# CC2538NF53 register map
File version: 1.0
CPU: CM3 1.0, other endian, MPU, FPU, 3 interrupt priority bits
Registers are 32-bit, read-write, reset 0x0 unless marked. A register's access mark holds for its fields unless they carry their own. Offsets are from the block's base; [hi:lo] are bit positions; {n}, {i} and the like mark numbered series.

## AES (part 2 of 2) — Register fields should be considered static unless otherwise noted as dynamic.
Base 0x4008B000
0x570 AES_TAG_OUT_0 — TAG registers The tag registers can be accessed via DMA or directly with host reads. These registers buffer the TAG from the EIP-120t. The registers are shared with the intermediate authentication result registers, but cannot be read until the processing is finished. While processing, a read from these registers returns 0s. If an operation does not return a TAG, reading from these registers returns an IV. If an operation returns a TAG plus an IV and both need to be read by the host, the host must first read the TAG followed by the IV. Reading these in reverse order will return the IV twice.
  [31:0] AES_TAG — [31:0] AES_TAG[31:0] Bits [31:0] of the AES_TAG registers store the authentication value for the combined and authentication only modes. For a host read operation, these registers contain the last 128-bit TAG output of the EIP-120t; the TAG is available until the next context is written. This register will only contain valid data if the TAG is available and when the store_ready bit from AES_CTRL register is set. During processing or for operations/modes that do not return a TAG, reads from this register return data from the IV register.
{0x570+4i} AES_TAG_OUT_{i} (i=1..3) — TAG registers The tag registers can be accessed via DMA or directly with host reads. These registers buffer the TAG from the EIP-120t. The registers are shared with the intermediate authentication result registers, but cannot be read until the processing is finished. While processing, a read from these registers returns 0s. If an operation does not return a TAG, reading from these registers returns an IV. If an operation returns a TAG plus an IV and both need to be read by the host, the host must first read the TAG followed by the IV. Reading these in reverse order returns the IV twice.
  [31:0] AES_TAG — [31:0] AES_TAG[{32i+31}:{32i}] For a host read operation, these registers contain the last 128-bit TAG output of the EIP-120t; the TAG is available until the next context is written. This register contains valid data only if the TAG is available and when the store_ready bit from AES_CTRL register is set. During processing or for operations/modes that do not return a TAG, reads from this register return data from the IV register.
{0x600+4i} HASH_DATA_IN_{i} (i=0..15) — HASH data input registers The data input registers should be used to provide input data to the hash module through the slave interface.
  [31:0] HASH_DATA_IN — [31:0] HASH_DATA_IN[{32i+31}:{32i}] These registers must be written with the 512-bit input data. The data lines are connected directly to the data input of the hash module and hence into the engine's internal data buffer. Writing to each of the registers triggers a corresponding 32-bit write enable to the internal buffer. Note: The host may only write the input data buffer when the rfd_in bit of the HASH_IO_BUF_CTRL register is high. If the rfd_in bit is 0, the engine is busy with processing. During processing, it is not allowed to write new input data. For message lengths larger than 64 bytes, multiple blocks of data are written to this input buffer using a handshake through flags of the HASH_IO_BUF_CTRL register. All blocks except the last are required to be 512 bits in size. If the last block is not 512 bits long, only the least significant bits of data must be written, but they must be padded with 0s to the next 32-bit boundary. Host read operations from these register addresses return 0s.
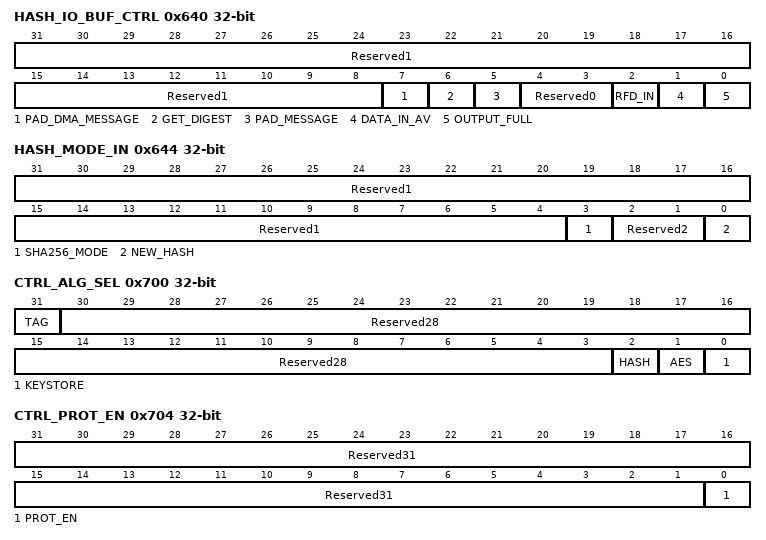
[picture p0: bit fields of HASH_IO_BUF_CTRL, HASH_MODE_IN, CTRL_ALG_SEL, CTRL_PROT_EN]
0x640 HASH_IO_BUF_CTRL — Input/output buffer control and status register This register pair shares a single address location and contains bits that control and monitor the data flow between the host and the hash engine.
  [31:8] Reserved1 — [31:8] Write 0s and ignore on reading
  [7] PAD_DMA_MESSAGE — [7:7] Note: This bit must only be used when data is supplied through the DMA. It should not be used when data is supplied through the slave interface. This bit indicates whether the hash engine has to pad the message, received through the DMA and finalize the hash. When set to 1, the hash engine pads the last block using the programmed length. After padding, the final hash result is calculated. When set to 0, the hash engine treats the last written block as block-size aligned and calculates the intermediate digest. This bit is automatically cleared when the last DMA data block is arrived in the hash engine.
  [6] GET_DIGEST — [6:6] Note: The bit description below is only applicable when data is sent through the slave interface. This bit must be set to 0 when data is received through the DMA. This bit indicates whether the hash engine should provide the hash digest. When provided simultaneously with data_in_av, the hash digest is provided after processing the data that is currently in the HASH_DATA_IN register. When provided without data_in_av, the current internal digest buffer value is copied to the HASH_DIGEST_n registers. The host must write a 1 to this bit to make the intermediate hash digest available. Writing 0 to this bit has no effect. This bit is automatically cleared (that is, reads 0) when the hash engine has processed the contents of the HASH_DATA_IN register. In the period between this bit is set by the host and the actual HASH_DATA_IN processing, this bit reads 1.
  [5] PAD_MESSAGE — [5:5] Note: The bit description below is only applicable when data is sent through the slave interface. This bit must be set to 0 when data is received through the DMA. This bit indicates that the HASH_DATA_IN registers hold the last data of the message and hash padding must be applied. The host must write this bit to 1 in order to indicate to the hash engine that the HASH_DATA_IN register currently holds the last data of the message. When pad_message is set to 1, the hash engine will add padding bits to the data currently in the HASH_DATA_IN register. When the last message block is smaller than 512 bits, the pad_message bit must be set to 1 together with the data_in_av bit. When the last message block is equal to 512 bits, pad_message may be set together with data_in_av. In this case the pad_message bit may also be set after the last data block has been written to the hash engine (so when the rfd_in bit has become 1 again after writing the last data block). Writing 0 to this bit has no effect. This bit is automatically cleared (i.e. reads 0) by the hash engine. This bit reads 1 between the time it was set by the host and the hash engine interpreted its value.
  [4:3] Reserved0 — [4:3] Write 0s and ignore on reading
  [2] RFD_IN — [2:2] Note: The bit description below is only applicable when data is sent through the slave interface. This bit can be ignored when data is received through the DMA. Read-only status of the input buffer of the hash engine. When 1, the input buffer of the hash engine can accept new data; the HASH_DATA_IN registers can safely be populated with new data. When 0, the input buffer of the hash engine is processing the data that is currently in HASH_DATA_IN; writing new data to these registers is not allowed.
  [1] DATA_IN_AV — [1:1] Note: The bit description below is only applicable when data is sent through the slave interface. This bit must be set to 0 when data is received through the DMA. This bit indicates that the HASH_DATA_IN registers contain new input data for processing. The host must write a 1 to this bit to start processing the data in HASH_DATA_IN; the hash engine will process the new data as soon as it is ready for it (rfd_in bit is 1). Writing 0 to this bit has no effect. This bit is automatically cleared (i.e. reads as 0) when the hash engine starts processing the HASH_DATA_IN contents. This bit reads 1 between the time it was set by the host and the hash engine actually starts processing the input data block.
  [0] OUTPUT_FULL — [0:0] Indicates that the output buffer registers (HASH_DIGEST_n) are available for reading by the host. When this bit reads 0, the output buffer registers are released; the hash engine is allowed to write new data to it. In this case, the registers should not be read by the host. When this bit reads 1, the hash engine has stored the result of the latest hash operation in the output buffer registers. As long as this bit reads 1, the host may read output buffer registers and the hash engine is prevented from writing new data to the output buffer. After retrieving the hash result data from the output buffer, the host must write a 1 to this bit to clear it. This makes the digest output buffer available for the hash engine to store new hash results. Writing 0 to this bit has no effect. Note: If this bit is asserted (1) no new operation should be started before the digest is retrieved from the hash engine and this bit is cleared (0).
0x644 HASH_MODE_IN — Hash mode register
  [31:4] Reserved1 — [31:4] Write 0s and ignore on reading
  [3] SHA256_MODE — [3:3] The host must write this bit with 1 before processing a hash session.
  [2:1] Reserved2 — [2:1] Write 0s and ignore on reading
  [0] NEW_HASH — [0:0] When set to 1, it indicates that the hash engine must start processing a new hash session. The HASH_DIGEST_n registers will automatically be loaded with the initial hash algorithm constants of the selected hash algorithm. When this bit is 0 while the hash processing is started, the initial hash algorithm constants are not loaded in the HASH_DIGEST_n registers. The hash engine will start processing with the digest that is currently in its internal HASH_DIGEST_n registers. This bit is automatically cleared when hash processing is started.
0x648 HASH_LENGTH_IN_L — Hash length register
  [31:0] LENGTH_IN — [31:0] LENGTH_IN[31:0] Message length registers. The content of these registers is used by the hash engine during the message padding phase of the hash session. The data lines of this registers are directly connected to the interface of the hash engine. For a write operation by the host, these registers should be written with the message length in bits. Final hash operations: The total input data length must be programmed for new hash operations that require finalization (padding). The input data must be provided through the slave or DMA interface. Continued hash operations (finalized): For continued hash operations that require finalization, the total message length must be programmed, including the length of previously hashed data that corresponds to the written input digest. Non-final hash operations: For hash operations that do not require finalization (input data length is multiple of 512-bits which is SHA-256 data block size), the length field does not need to be programmed since not used by the operation. If the message length in bits is below (2^32-1), then only HASH_LENGTH_IN_L needs to be written. The hardware automatically sets HASH_LENGTH_IN_H to 0s in this case. The host may write the length register at any time during the hash session when the rfd_in bit of the HASH_IO_BUF_CTRL is high. The length register must be written before the last data of the active hash session is written into the hash engine. host read operations from these register locations will return 0s. Note: When getting data from DMA, this register must be programmed before DMA is programmed to start.
0x64C HASH_LENGTH_IN_H — Hash length register
  [31:0] LENGTH_IN — [31:0] LENGTH_IN[63:32] Message length registers. The content of these registers is used by the hash engine during the message padding phase of the hash session. The data lines of this registers are directly connected to the interface of the hash engine. For a write operation by the host, these registers should be written with the message length in bits. Final hash operations: The total input data length must be programmed for new hash operations that require finalization (padding). The input data must be provided through the slave or DMA interface. Continued hash operations (finalized): For continued hash operations that require finalization, the total message length must be programmed, including the length of previously hashed data that corresponds to the written input digest. Non-final hash operations: For hash operations that do not require finalization (input data length is multiple of 512-bits which is SHA-256 data block size), the length field does not need to be programmed since not used by the operation. If the message length in bits is below (2^32-1), then only HASH_LENGTH_IN_L needs to be written. The hardware automatically sets HASH_LENGTH_IN_H to 0s in this case. The host may write the length register at any time during the hash session when the rfd_in bit of the HASH_IO_BUF_CTRL is high. The length register must be written before the last data of the active hash session is written into the hash engine. host read operations from these register locations will return 0s. Note: When getting data from DMA, this register must be programmed before DMA is programmed to start.
0x650 HASH_DIGEST_A — Hash digest registers The hash digest registers consist of eight 32-bit registers, named HASH_DIGEST_A to HASH_DIGEST_H. After processing a message, the output digest can be read from these registers. These registers can be written with an intermediate hash result for continued hash operations.
  [31:0] HASH_DIGEST — [31:0] HASH_DIGEST[31:0] Hash digest registers Write operation: Continued hash: These registers should be written with the context data, before the start of a resumed hash session (the new_hash bit in the HASH_MODE register is 0 when starting a hash session). New hash: When initiating a new hash session (the new_hash bit in the HASH_MODE register is high), the internal digest registers are automatically set to the SHA-256 algorithm constant and these register should not be written. Reading from these registers provides the intermediate hash result (non-final hash operation) or the final hash result (final hash operation) after data processing.
0x654 HASH_DIGEST_B — Hash digest registers The hash digest registers consist of eight 32-bit registers, named HASH_DIGEST_A to HASH_DIGEST_H. After processing a message, the output digest can be read from these registers. These registers can be written with an intermediate hash result for continued hash operations.
  [31:0] HASH_DIGEST — [31:0] HASH_DIGEST[63:32] Hash digest registers Write operation: Continued hash: These registers should be written with the context data, before the start of a resumed hash session (the new_hash bit in the HASH_MODE register is 0 when starting a hash session). New hash: When initiating a new hash session (the new_hash bit in the HASH_MODE register is high), the internal digest registers are automatically set to the SHA-256 algorithm constant and these register should not be written. Reading from these registers provides the intermediate hash result (non-final hash operation) or the final hash result (final hash operation) after data processing.
0x658 HASH_DIGEST_C — Hash digest registers The hash digest registers consist of eight 32-bit registers, named HASH_DIGEST_A to HASH_DIGEST_H. After processing a message, the output digest can be read from these registers. These registers can be written with an intermediate hash result for continued hash operations.
  [31:0] HASH_DIGEST — [31:0] HASH_DIGEST[95:64] Hash digest registers Write operation: Continued hash: These registers should be written with the context data, before the start of a resumed hash session (the new_hash bit in the HASH_MODE register is 0 when starting a hash session). New hash: When initiating a new hash session (the new_hash bit in the HASH_MODE register is high), the internal digest registers are automatically set to the SHA-256 algorithm constant and these register should not be written. Reading from these registers provides the intermediate hash result (non-final hash operation) or the final hash result (final hash operation) after data processing.
0x65C HASH_DIGEST_D — Hash digest registers The hash digest registers consist of eight 32-bit registers, named HASH_DIGEST_A to HASH_DIGEST_H. After processing a message, the output digest can be read from these registers. These registers can be written with an intermediate hash result for continued hash operations.
  [31:0] HASH_DIGEST — [31:0] HASH_DIGEST[127:96] Hash digest registers Write operation: Continued hash: These registers should be written with the context data, before the start of a resumed hash session (the new_hash bit in the HASH_MODE register is 0 when starting a hash session). New hash: When initiating a new hash session (the new_hash bit in the HASH_MODE register is high), the internal digest registers are automatically set to the SHA-256 algorithm constant and these register should not be written. Reading from these registers provides the intermediate hash result (non-final hash operation) or the final hash result (final hash operation) after data processing.
0x660 HASH_DIGEST_E — Hash digest registers The hash digest registers consist of eight 32-bit registers, named HASH_DIGEST_A to HASH_DIGEST_H. After processing a message, the output digest can be read from these registers. These registers can be written with an intermediate hash result for continued hash operations.
  [31:0] HASH_DIGEST — [31:0] HASH_DIGEST[159:128] Hash digest registers Write operation: Continued hash: These registers should be written with the context data, before the start of a resumed hash session (the new_hash bit in the HASH_MODE register is 0 when starting a hash session). New hash: When initiating a new hash session (the new_hash bit in the HASH_MODE register is high), the internal digest registers are automatically set to the SHA-256 algorithm constant and these register should not be written. Reading from these registers provides the intermediate hash result (non-final hash operation) or the final hash result (final hash operation) after data processing.
0x664 HASH_DIGEST_F — Hash digest registers The hash digest registers consist of eight 32-bit registers, named HASH_DIGEST_A to HASH_DIGEST_H. After processing a message, the output digest can be read from these registers. These registers can be written with an intermediate hash result for continued hash operations.
  [31:0] HASH_DIGEST — [31:0] HASH_DIGEST[191:160] Hash digest registers Write operation: Continued hash: These registers should be written with the context data, before the start of a resumed hash session (the new_hash bit in the HASH_MODE register is 0 when starting a hash session). New hash: When initiating a new hash session (the new_hash bit in the HASH_MODE register is high), the internal digest registers are automatically set to the SHA-256 algorithm constant and these register should not be written. Reading from these registers provides the intermediate hash result (non-final hash operation) or the final hash result (final hash operation) after data processing.
0x668 HASH_DIGEST_G — Hash digest registers The hash digest registers consist of eight 32-bit registers, named HASH_DIGEST_A to HASH_DIGEST_H. After processing a message, the output digest can be read from these registers. These registers can be written with an intermediate hash result for continued hash operations.
  [31:0] HASH_DIGEST — [31:0] HASH_DIGEST[223:192] Hash digest registers Write operation: Continued hash: These registers should be written with the context data, before the start of a resumed hash session (the new_hash bit in the HASH_MODE register is 0 when starting a hash session). New hash: When initiating a new hash session (the new_hash bit in the HASH_MODE register is high), the internal digest registers are automatically set to the SHA-256 algorithm constant and these register should not be written. Reading from these registers provides the intermediate hash result (non-final hash operation) or the final hash result (final hash operation) after data processing.
0x66C HASH_DIGEST_H — Hash digest registers The hash digest registers consist of eight 32-bit registers, named HASH_DIGEST_A to HASH_DIGEST_H. After processing a message, the output digest can be read from these registers. These registers can be written with an intermediate hash result for continued hash operations.
  [31:0] HASH_DIGEST — [31:0] HASH_DIGEST[255:224] Hash digest registers Write operation: Continued hash: These registers should be written with the context data, before the start of a resumed hash session (the new_hash bit in the HASH_MODE register is 0 when starting a hash session). New hash: When initiating a new hash session (the new_hash bit in the HASH_MODE register is high), the internal digest registers are automatically set to the SHA-256 algorithm constant and these register should not be written. Reading from these registers provides the intermediate hash result (non-final hash operation) or the final hash result (final hash operation) after data processing.
0x700 CTRL_ALG_SEL — Algorithm select This algorithm selection register configures the internal destination of the DMA controller.
  [31] TAG — [31:31] If this bit is cleared to 0, the DMA operation involves only data. If this bit is set, the DMA operation includes a TAG (Authentication Result / Digest). For SHA-256 operation, a DMA must be set up for both input data and TAG. For any other selected module, setting this bit only allows a DMA that reads the TAG. No data allowed to be transferred to or from the selected module via the DMA.
  [30:3] Reserved28 — [30:3] Bits should be written with 0s and ignored on read.
  [2] HASH — [2:2] If set to one, selects the hash engine as destination for the DMA The maximum transfer size to DMA engine is set to 64 bytes for reading and 32 bytes for writing (the latter is only applicable if the hash result is written out through the DMA).
  [1] AES — [1:1] If set to one, selects the AES engine as source/destination for the DMA The read and write maximum transfer size to the DMA engine is set to 16 bytes.
  [0] KEYSTORE — [0:0] If set to one, selects the Key Store as destination for the DMA The maximum transfer size to DMA engine is set to 32 bytes (however transfers of 16, 24 and 32 bytes are allowed)
0x704 CTRL_PROT_EN — Master PROT privileged access enable This register enables the second bit (bit [1]) of the AHB HPROT bus of the AHB master interface when a read action of key(s) is performed on the AHB master interface for writing keys into the store module.
  [31:1] Reserved31 — [31:1] Bits should be written with 0s and ignored on read.
  [0] PROT_EN — [0:0] If this bit is cleared to 0, m_h_prot[1] on the AHB mater interface always remains 0. If this bit is set to one, the m_h_prot[1] signal on the master AHB bus is asserted to 1 if an AHB read operation is performed, using DMA, with the key store module as destination.
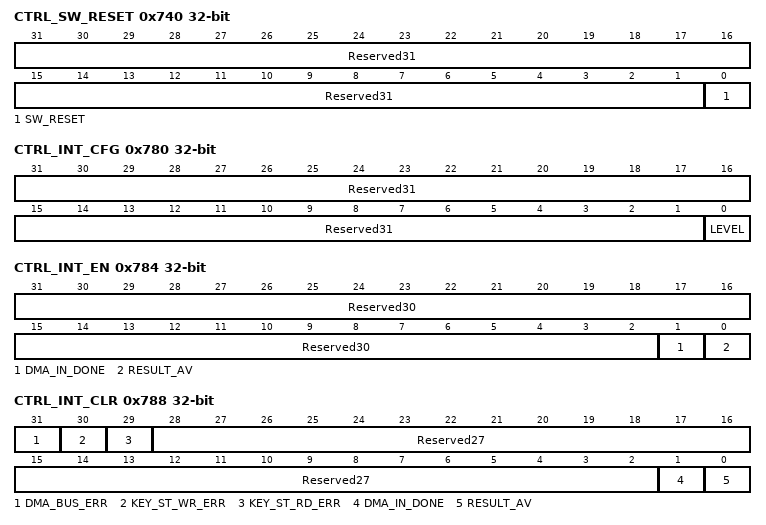
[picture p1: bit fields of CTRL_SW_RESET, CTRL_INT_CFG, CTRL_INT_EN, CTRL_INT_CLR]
0x740 CTRL_SW_RESET — Software reset
  [31:1] Reserved31 — [31:1] Bits should be written with 0s and ignored on read.
  [0] SW_RESET — [0:0] If this bit is set to 1, the following modules are reset: - Master control internal state is reset. That includes interrupt, error status register, and result available interrupt generation FSM. - Key store module state is reset. That includes clearing the written area flags; therefore, the keys must be reloaded to the key store module. Writing 0 has no effect. The bit is self cleared after executing the reset.
0x780 CTRL_INT_CFG — Interrupt configuration
  [31:1] Reserved31 — [31:1] Bits should be written with 0s and ignored on read.
  [0] LEVEL — [0:0] If this bit is 0, the interrupt output is a pulse. If this bit is set to 1, the interrupt is a level interrupt that must be cleared by writing the interrupt clear register. This bit is applicable for both interrupt output signals.
0x784 CTRL_INT_EN — Interrupt enable
  [31:2] Reserved30 — [31:2] Bits should be written with 0s and ignored on read.
  [1] DMA_IN_DONE — [1:1] If this bit is set to 0, the DMA input done (irq_dma_in_done) interrupt output is disabled and remains 0. If this bit is set to 1, the DMA input done interrupt output is enabled.
  [0] RESULT_AV — [0:0] If this bit is set to 0, the result available (irq_result_av) interrupt output is disabled and remains 0. If this bit is set to 1, the result available interrupt output is enabled.
0x788 CTRL_INT_CLR — Interrupt clear
  [31] DMA_BUS_ERR — [31:31] If 1 is written to this bit, the DMA bus error status is cleared. Writing 0 has no effect.
  [30] KEY_ST_WR_ERR — [30:30] If 1 is written to this bit, the key store write error status is cleared. Writing 0 has no effect.
  [29] KEY_ST_RD_ERR — [29:29] If 1 is written to this bit, the key store read error status is cleared. Writing 0 has no effect.
  [28:2] Reserved27 — [28:2] Bits should be written with 0s and ignored on read.
  [1] DMA_IN_DONE — [1:1] If 1 is written to this bit, the DMA in done (irq_dma_in_done) interrupt output is cleared. Writing 0 has no effect. Note that clearing an interrupt makes sense only if the interrupt output is programmed as level (refer to CTRL_INT_CFG).
  [0] RESULT_AV — [0:0] If 1 is written to this bit, the result available (irq_result_av) interrupt output is cleared. Writing 0 has no effect. Note that clearing an interrupt makes sense only if the interrupt output is programmed as level (refer to CTRL_INT_CFG).
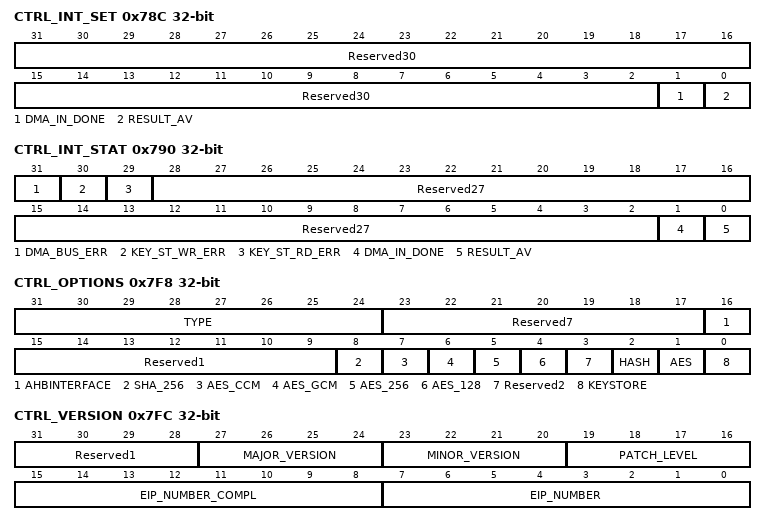
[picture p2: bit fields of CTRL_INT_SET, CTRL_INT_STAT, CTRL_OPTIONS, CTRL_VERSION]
0x78C CTRL_INT_SET — Interrupt set
  [31:2] Reserved30 — [31:2] Bits should be written with 0s and ignored on read.
  [1] DMA_IN_DONE — [1:1] If 1 is written to this bit, the DMA data in done (irq_dma_in_done) interrupt output is set to one. Writing 0 has no effect. If the interrupt configuration register is programmed to pulse, clearing the DMA data in done (irq_dma_in_done) interrupt is not needed. If it is programmed to level, clearing the interrupt output should be done by writing the interrupt clear register (CTRL_INT_CLR).
  [0] RESULT_AV — [0:0] If 1 is written to this bit, the result available (irq_result_av) interrupt output is set to one. Writing 0 has no effect. If the interrupt configuration register is programmed to pulse, clearing the result available (irq_result_av) interrupt is not needed. If it is programmed to level, clearing the interrupt output should be done by writing the interrupt clear register (CTRL_INT_CLR).
0x790 CTRL_INT_STAT — Interrupt status
  [31] DMA_BUS_ERR — [31:31] This bit is set when a DMA bus error is detected during a DMA operation. The value of this register is held until it is cleared through the CTRL_INT_CLR register. Note: This error is asserted if an error is detected on the AHB master interface during a DMA operation.
  [30] KEY_ST_WR_ERR — [30:30] This bit is set when a write error is detected during the DMA write operation to the key store memory. The value of this register is held until it is cleared through the CTRL_INT_CLR register. Note: This error is asserted if a DMA operation does not cover a full key area or more areas are written than expected.
  [29] KEY_ST_RD_ERR — [29:29] This bit is set when a read error is detected during the read of a key from the key store, while copying it to the AES core. The value of this register is held until it is cleared through the CTRL_INT_CLR register. Note: This error is asserted if a key location is selected in the key store that is not available.
  [28:2] Reserved27 — [28:2] Bits should be ignored
  [1] DMA_IN_DONE — [1:1] This read only bit returns the actual DMA data in done (irq_data_in_done) interrupt status of the DMA data in done interrupt output pin (irq_data_in_done).
  [0] RESULT_AV — [0:0] This read only bit returns the actual result available (irq_result_av) interrupt status of the result available interrupt output pin (irq_result_av).
0x7F8 CTRL_OPTIONS — Options register
  [31:24] TYPE — [31:24] This field is 0x01 for the TYPE1 device.
  [23:17] Reserved7 — [23:17] Bits should be ignored
  [16] AHBINTERFACE — [16:16] AHB interface is available If this bit is 0, the EIP-120t has a TCM interface.
  [15:9] Reserved1 — [15:9] Bits should be ignored
  [8] SHA_256 — [8:8] The HASH core supports SHA-256.
  [7] AES_CCM — [7:7] AES-CCM is available as a single operation.
  [6] AES_GCM — [6:6] AES-GCM is available as a single operation.
  [5] AES_256 — [5:5] AES core supports 256-bit keys Note: If both AES-128 and AES-256 are set to one, the AES core supports 192-bit keys as well.
  [4] AES_128 — [4:4] AES core supports 128-bit keys.
  [3] Reserved2 — [3:3] Bit should be ignored
  [2] HASH — [2:2] HASH Core is available.
  [1] AES — [1:1] AES core is available.
  [0] KEYSTORE — [0:0] KEY STORE is available.
0x7FC CTRL_VERSION — Version register
  [31:28] Reserved1 — [31:28] Bit should be ignored
  [27:24] MAJOR_VERSION — [27:24] Major version number
  [23:20] MINOR_VERSION — [23:20] Minor version number
  [19:16] PATCH_LEVEL — [19:16] Patch level Starts at 0 at first delivery of this version
  [15:8] EIP_NUMBER_COMPL — [15:8] These bits simply contain the complement of bits [7:0] (0x87), used by a driver to ascertain that the EIP-120t register is indeed read.
  [7:0] EIP_NUMBER — [7:0] These bits encode the EIP number for the EIP-120t, this field contains the value 120 (decimal) or 0x78.
